# FM33A0XXX register map
File version: 1.0
CPU: SC000 r1p0, little endian, MPU, no FPU, 3 interrupt priority bits
Registers are 32-bit, read-write, reset 0x0 unless marked. A register's access mark holds for its fields unless they carry their own. Offsets are from the block's base; [hi:lo] are bit positions; {n}, {i} and the like mark numbered series.

## U7816_0 — U7816_0 Registers
Base 0x40011C00
Same registers: U7816_1 0x40011C2C
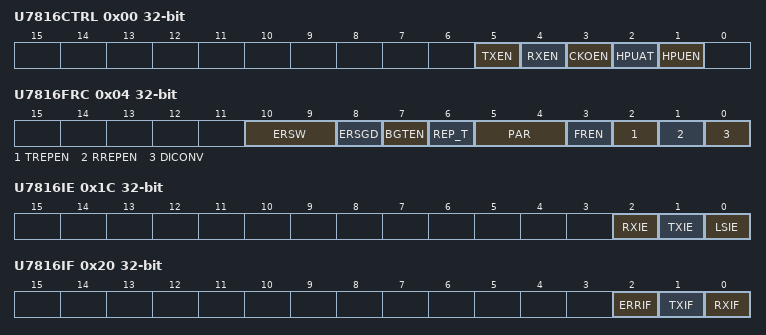
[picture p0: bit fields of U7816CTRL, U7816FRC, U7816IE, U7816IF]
0x00 U7816CTRL — U7816 CONTROL REGISTER
  [5] TXEN — TX ENABLE
    0=TX_DIS (TX DISABLE); 1=TX_EN (TX ENABLE)
  [4] RXEN — RX ENABLE
    0=RX_DIS (RX DISABLE); 1=RX_EN (RX ENABLE)
  [3] CKOEN — CLK OUTPUT ENABLE
    0=CKO_DIS (CLK OUPUT DISABLE); 1=CKO_EN (CLK OUTPUT ENABLE)
  [2] HPUAT — AUTO PULLUP ENABLE
    0=DISABLE (AUTO PULLUP DISABLE); 1=ENABLE (AUTO PULLUP ENABLE)
  [1] HPUEN — PULLUP ENABLE
    0=DISABLE (PULLUP DISABLE); 1=ENABLE (PULLUP ENABLE)
0x04 U7816FRC — U7816 FRAME CONTROL
  [10:9] ERSW — ERROR SIGNAL LENGTH
    0=2ETU; 1=2ETU; 2=1.5ETU; 3=1ETU
  [8] ERSGD — GUARDTIME LENGTH AFTER ERROR SIGNAL
    0=2.5ETU (2~2.5ETU); 1=1.5ETU (1~1.5ETU)
  [7] BGTEN — block guard time enable
    0=BGT_DIS (BGT DISABLE); 1=BGT_EN
  [6] REP_T — REPEAT TIME
    0=1T; 1=3T
  [5:4] PAR — PARITY MODE
    0=Even; 1=Odd; 2=Always1; 3=NOT_HANDLE
  [3] FREN — Guard Time Length
    0=2ETU; 1=1ETU
  [2] TREPEN — AUTO POSTBACK WHEN RECEIVED ERROR SIGNAL
  [1] RREPEN — AUTO POSTBACK ERROR SIGNAL WHEN PARITY_ERR
  [0] DICONV — DIRECTION CONV
    0=LSB (LSB FIRST); 1=MSB (MSB FIRST)
0x08 U7816EGT — U7816 EGT config
  [7:0] TXEGT
0x0C U7816CLKDIV — U7816 CLK DIVIDED CONFIG
  [4:0] CLKDIV — CLK DIVIDED F7816=FAPBCLK/(CLKDIV+1)
0x10 U7816PDIV — U7816 FREQ DIVISION CONFIG
  [11:0] PDIV — Baud = F7816/(PDIV+1)
0x14 U7816RXBUF
  [7:0] RXBUF
0x18 U7816TXBUF
  [7:0] TXBUF
0x1C U7816IE
  [2] RXIE
  [1] TXIE
  [0] LSIE — FOR ERROR_FLAG
0x20 U7816IF
  [2] ERRIF, [1] TXIF, [0] RXIF
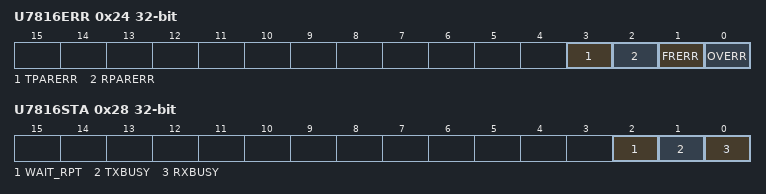
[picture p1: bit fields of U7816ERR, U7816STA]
0x24 U7816ERR — U7816 ERR FLAG REGISTER
  [3] TPARERR — TX PARITY ERROR
  [2] RPARERR — RX PARITY ERROR
  [1] FRERR — FRAME ERROR
  [0] OVERR — OVerflow ERROR
0x28 U7816STA — U7816 STATUS REGISTER
  [2] WAIT_RPT, [1] TXBUSY, [0] RXBUSY

## UART_COMMON — UART_COMMON Registers
Base 0x40012000
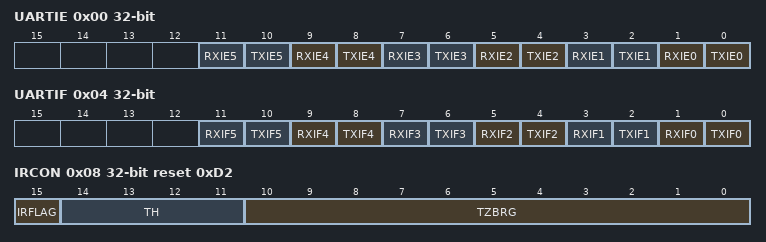
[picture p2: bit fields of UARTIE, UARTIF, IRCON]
0x00 UARTIE
  [2n+1] RXIE{n} (n=0..5), [2n] TXIE{n} (n=0..5)
0x04 UARTIF
  [2n+1] RXIF{n} (n=0..5), [2n] TXIF{n} (n=0..5)
0x08 IRCON reset 0xD2 — IR CONFIG
  [15] IRFLAG
  [14:11] TH — duty cuycle Y = (TZBRG[10:4] * TH) /(TZBRG+1)
  [10:0] TZBRG — FIR = Fpclk / (TZBRG +1)

## UART0 — UART0 Registers
Base 0x4001200C
Same registers: UART1 0x4001202C, UART2 0x4001204C, UART3 0x4001206C, UART4 0x4001208C, UART5 0x400120AC
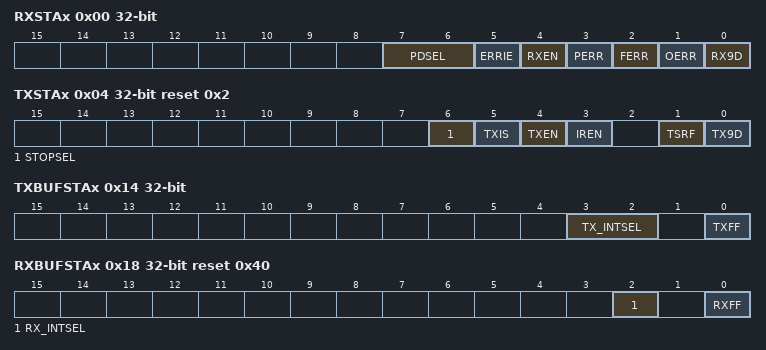
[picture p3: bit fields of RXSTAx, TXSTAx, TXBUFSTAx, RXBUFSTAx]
0x00 RXSTAx — RX STATUS
  [7:6] PDSEL — PARITY MODE SELECT
    0=8NONE (8BIT,NO PARITY); 1=8EVEN (8BIT,EVEN PARITY); 2=8ODD (8BIT,ODD PARITY); 3=9NONE (9BIT,NO PARITY)
  [5] ERRIE
  [4] RXEN — RX ENABLE
  [3] PERR — Parity ERR
  [2] FERR — Frame ERR
  [1] OERR — Overflow ERR
  [0] RX9D ro — RX BIT9
0x04 TXSTAx reset 0x2 — TX STATUS
  [6] STOPSEL — STOP BIT select
    0=1BIT (1 STOPBIT); 1=2BIT (2 STOPBIT)
  [5] TXIS — TX Interupt Select
    0=TXBUF (INT AT TXBUF EMPTY); 1=TSR (INT AT TSR EMPTY)
  [4] TXEN — TX ENable
  [3] IREN — IR ENable
  [1] TSRF — Tx Shift Register empty Flag
  [0] TX9D — TX bit9
0x08 RXREGx ro
  [7:0] RXREGx rw
0x0C TXREGx wo
  [7:0] TXREG
0x10 SPBRG reset 0x341 — baudrate setting register
  [15:0] SPBRG — Baud = FAPBCLK / (SPBRG+1)
0x14 TXBUFSTAx — TX BUF STAtus
  [3:2] TX_INTSEL
    0=TXIS; 1=TSF; 2=TBUF; 3=NONE
  [0] TXFF — TX buff Full Flag
    0=EMPTY; 1=FULL
0x18 RXBUFSTAx reset 0x40 — RX BUF STATUS
  [2] RX_INTSEL
    0=REV_FINISH; 1=RXBUF_FULL
  [0] RXFF — RX FULL FLAG
    0=EMPTY; 1=1BYTE
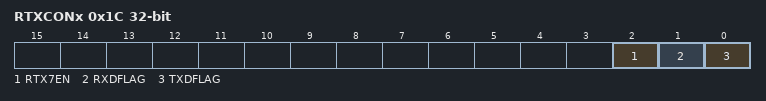
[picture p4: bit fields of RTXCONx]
0x1C RTXCONx — RTX CONVERSE REGISTER
  [2] RTX7EN — RTX BIT7 CONTROL BIT
  [1] RXDFLAG — RX REVERSE CONTROL BIT
  [0] TXDFLAG — TX REVERSE CONTROL BIT

## I2C — I2C Registers
Base 0x40012400
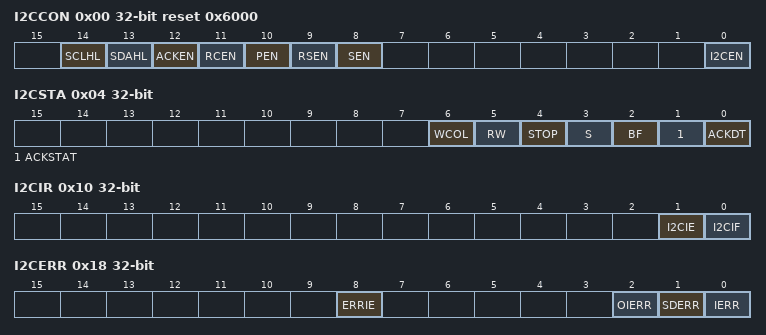
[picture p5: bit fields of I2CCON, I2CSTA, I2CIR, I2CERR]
0x00 I2CCON reset 0x6000 — I2C CONTROL REGISTER
  [14] SCLHL — SCL PULL HIGH AT I2C DISABLE
  [13] SDAHL — SDA PULL HIGH AT I2C DISABLE
  [12] ACKEN — AUTO ACK ENABLE AT MASTER
  [11] RCEN — RECEIVE ENABLE
  [10] PEN — STOP SEQUENCE ENABLE
  [9] RSEN — REPEAT SYART ENABLE
  [8] SEN — START SEQUENCE ENABLE
  [0] I2CEN
0x04 I2CSTA — I2C STATUS
  [6] WCOL — write collision
  [5] RW ro — BUSY
  [4] STOP ro — detect stop sequence
  [3] S ro — detect start sequence
  [2] BF ro — BUFF FULL
    0=EMPTY (SSPBUF EMPTY); 1=FULL (SSPBUF FULL)
  [1] ACKSTAT — ACK STATE FROM SLAVE
    0=RACK0 (RECEIVE ACK 0 FROM SLAVE); 1=RACKN (RECEIVE ACK NONE FROM SLAVE)
  [0] ACKDT — MASTER RESPOND NONE
    0=MRP0 (MASTER RESPOND 0); 1=MRPN (MASTER RESPOND NONE)
0x08 I2CBRG reset 0x13 — I2C BAUDRATE
  [8:0] BRG — Baud = FAPBCLK/((BRG+1)MUL4)
0x0C I2CBUF
  [7:0] I2CBUF
0x10 I2CIR — I2C INTERRUPT REGISTER
  [1] I2CIE
  [0] I2CIF — I2C IF,write 1 to clear
0x14 I2CFSM
  [3:0] I2CFSM
    0=IDLE; 1=START1; 2=START2; 3=START_DONE; 4=TX_STATE; 5=RCACK; 6=OP_IDLE; 7=STOP1; 8=STOP2; 9=STOP_DONE; 10=RTP_START; 11=RX_STATE; 12=ACT_STATE; 13=STOP0
0x18 I2CERR
  [8] ERRIE
  [2] OIERR — OP_IDLE ERR
  [1] SDERR — START_DONE ERR
  [0] IERR — IDLE ERR
